# PIC32CX5109BZ31032 device description
Architecture: CORTEX-M4; Family: PIC32CX; Series: PIC32CXBZ31
Registers are 32-bit, read-write, reset 0x0 unless marked. A register's access mark holds for its fields unless they carry their own. Offsets are from the block's base; [hi:lo] are bit positions; {n}, {i} and the like mark numbered series.

## ETM — Embedded Trace Macrocell
Instances: ETM 0xE0041000
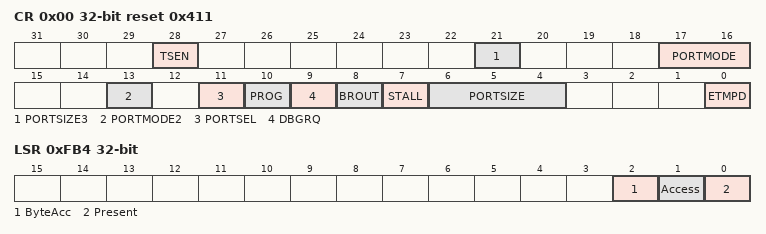
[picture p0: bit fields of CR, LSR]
0x00 CR reset 0x411 — ETM Main Control Register
  [28] TSEN — TimeStamp Enable
  [21] PORTSIZE3 — Port Size bit 3
  [17:16] PORTMODE — Port Mode bits 1:0
  [13] PORTMODE2 — Port Mode bit 2
  [11] PORTSEL — ETM Port Select
  [10] PROG — ETM Programming
  [9] DBGRQ — Debug Request Control
  [8] BROUT — Branch Output
  [7] STALL — Stall Processor
  [6:4] PORTSIZE — Port Size bits 2:0
  [0] ETMPD — ETM Power Down
0x04 CCR ro reset 0x8C802000 — ETM Configuration Code Register
0x08 TRIGGER reset not defined — ETM Trigger Event Register
0x10 SR reset not defined — ETM Status Register
0x14 SCR ro reset 0x20D09 (atomic clear of SR) — ETM System Configuration Register
0x20 TEEVR reset not defined — ETM TraceEnable Event Register
0x24 TECR1 reset not defined — ETM TraceEnable Control 1 Register
0x28 FFLR reset not defined — ETM FIFO Full Level Register
0x140 CNTRLDVR1 reset not defined — ETM Free-running Counter Reload Value
0x1E0 SYNCFR ro reset 0x400 — ETM Synchronization Frequency Register
0x1E4 IDR ro reset 0x4114F250 — ETM ID Register
0x1E8 CCER ro reset 0x18541800 — ETM Configuration Code Extension Register
0x1F0 TESSEICR reset not defined — ETM TraceEnable Start/Stop EmbeddedICE Control Register
0x1F8 TSEVT reset not defined — ETM TimeStamp Event Register
0x200 TRACEIDR — ETM CoreSight Trace ID Register
0x208 IDR2 ro — ETM ID Register 2
0x314 PDSR ro reset 0x1 — ETM Device Power-Down Status Register
0xEE0 ITMISCIN ro reset not defined — ETM Integration Test Miscellaneous Inputs
0xEE8 ITTRIGOUT wo reset not defined — ETM Integration Test Trigger Out
0xEF0 ITATBCTR2 ro reset not defined — ETM Integration Test ATB Control 2
0xEF8 ITATBCTR0 wo reset not defined — ETM Integration Test ATB Control 0
0xF00 ITCTRL — ETM Integration Mode Control Register
  [0] INTEGRATION
0xFA0 CLAIMSET reset not defined (atomic set) — ETM Claim Tag Set Register
0xFA4 CLAIMCLR reset not defined (atomic clear) — ETM Claim Tag Clear Register
0xFB0 LAR wo reset not defined — ETM Lock Access Register
0xFB4 LSR ro reset not defined — ETM Lock Status Register
  [2] ByteAcc, [1] Access, [0] Present
0xFB8 AUTHSTATUS ro reset not defined — ETM Authentication Status Register
0xFCC DEVTYPE ro reset 0x13 — ETM CoreSight Device Type Register
0xFD0 PIDR4 ro reset 0x4 — ETM Peripheral Identification Register #4
{0xFC0+4i} PIDR{i} ro (i=5..7) — ETM Peripheral Identification Register #{i}
0xFE0 PIDR0 ro reset 0x25 — ETM Peripheral Identification Register #0
0xFE4 PIDR1 ro reset 0xB9 — ETM Peripheral Identification Register #1
0xFE8 PIDR2 ro reset 0xB — ETM Peripheral Identification Register #2
0xFEC PIDR3 ro — ETM Peripheral Identification Register #3
0xFF0 CIDR0 ro reset 0xD — ETM Component Identification Register #0
0xFF4 CIDR1 ro reset 0x90 — ETM Component Identification Register #1
0xFF8 CIDR2 ro reset 0x5 — ETM Component Identification Register #2
0xFFC CIDR3 ro reset 0xB1 — ETM Component Identification Register #3

## FPU — Floating Point Unit
Instances: FPU 0xE000EF30
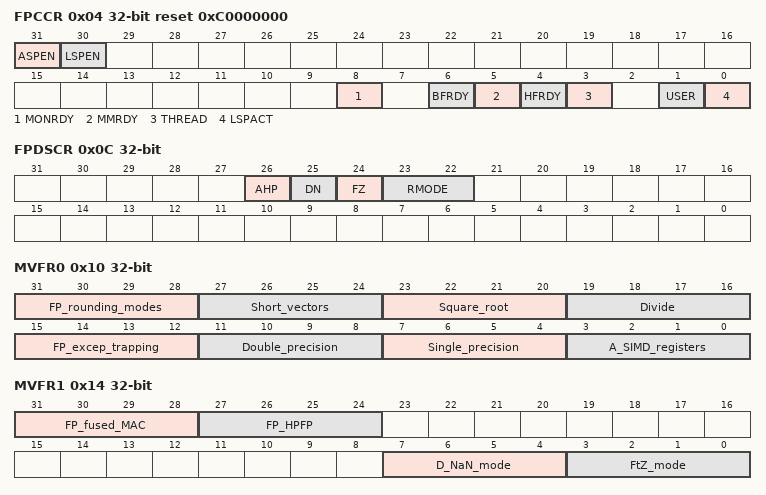
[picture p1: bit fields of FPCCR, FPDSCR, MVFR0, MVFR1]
0x04 FPCCR reset 0xC0000000 — Floating-Point Context Control Register
  [31] ASPEN, [30] LSPEN, [8] MONRDY, [6] BFRDY, [5] MMRDY, [4] HFRDY, [3] THREAD, [1] USER, [0] LSPACT
0x08 FPCAR reset not defined — Floating-Point Context Address Register
  [31:3] ADDRESS — Address for FP registers in exception stack frame
0x0C FPDSCR — Floating-Point Default Status Control Register
  [26] AHP — Default value for FPSCR.AHP
  [25] DN — Default value for FPSCR.DN
  [24] FZ — Default value for FPSCR.FZ
  [23:22] RMODE — Default value for FPSCR.RMODE
    0=RN (Round to Nearest); 1=RP (Round towards Positive Infinity); 2=RM (Round towards Negative Infinity); 3=RZ (Round towards Zero)
0x10 MVFR0 ro reset not defined — Media and FP Feature Register 0
  [31:28] FP_rounding_modes, [27:24] Short_vectors, [23:20] Square_root, [19:16] Divide, [15:12] FP_excep_trapping, [11:8] Double_precision, [7:4] Single_precision, [3:0] A_SIMD_registers
0x14 MVFR1 ro reset not defined — Media and FP Feature Register 1
  [31:28] FP_fused_MAC, [27:24] FP_HPFP, [7:4] D_NaN_mode, [3:0] FtZ_mode
